AUTOSAR XML (schema 00046)
package /ComponentTypes
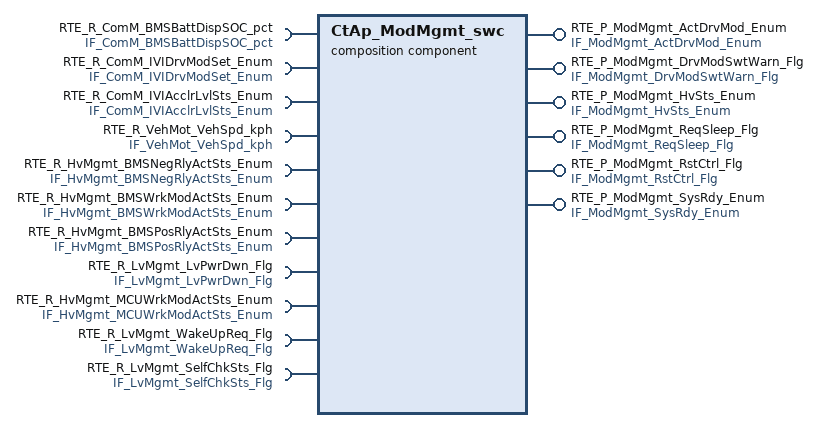
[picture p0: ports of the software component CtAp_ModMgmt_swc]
  composition sw component type CtAp_ModMgmt_swc
    5 x provide port:
      RTE_P_ModMgmt_ActDrvMod_Enum: nonqueued-sender-com-spec{data-element=tec_ModMgmt_ActDrvMod_Enum, init-value=0}, provided-interface=IF_ModMgmt_ActDrvMod_Enum
      RTE_P_ModMgmt_DrvModSwtWarn_Flg: nonqueued-sender-com-spec{data-element=tec_ModMgmt_DrvModSwtWarn_Flg, init-value=0}, provided-interface=IF_ModMgmt_DrvModSwtWarn_Flg
      RTE_P_ModMgmt_HvSts_Enum: nonqueued-sender-com-spec{data-element=tec_ModMgmt_HvSts_Enum, init-value=0}, provided-interface=IF_ModMgmt_HvSts_Enum
      RTE_P_ModMgmt_ReqSleep_Flg: nonqueued-sender-com-spec{data-element=tec_ModMgmt_ReqSleep_Flg, init-value=0}, provided-interface=IF_ModMgmt_ReqSleep_Flg
      RTE_P_ModMgmt_RstCtrl_Flg: nonqueued-sender-com-spec{data-element=tec_ModMgmt_RstCtrl_Flg, init-value=0}, provided-interface=IF_ModMgmt_RstCtrl_Flg
    4 x require port:
      RTE_R_ComM_BMSBattDispSOC_pct: nonqueued-receiver-com-spec{data-element=tec_ComM_BMSBattDispSOC_pct, filter=data-filter-type=ALWAYS, init-value=0}, required-interface=IF_ComM_BMSBattDispSOC_pct
      RTE_R_ComM_IVIDrvModSet_Enum: nonqueued-receiver-com-spec{data-element=tec_ComM_IVIDrvModSet_Enum, filter=data-filter-type=ALWAYS, init-value=0}, required-interface=IF_ComM_IVIDrvModSet_Enum
      RTE_R_ComM_IVIAcclrLvlSts_Enum: nonqueued-receiver-com-spec{data-element=tec_ComM_IVIAcclrLvlSts_Enum, filter=data-filter-type=ALWAYS, init-value=0}, required-interface=IF_ComM_IVIAcclrLvlSts_Enum
      RTE_R_VehMot_VehSpd_kph: nonqueued-receiver-com-spec{data-element=tec_VehMot_VehSpd_kph, filter=data-filter-type=ALWAYS, init-value=0}, required-interface=IF_VehMot_VehSpd_kph
    provide port RTE_P_ModMgmt_SysRdy_Enum: nonqueued-sender-com-spec{data-element=tec_ModMgmt_SysRdy_Enum, init-value=0}, provided-interface=IF_ModMgmt_SysRdy_Enum
    7 x require port:
      RTE_R_HvMgmt_BMSNegRlyActSts_Enum: nonqueued-receiver-com-spec{data-element=tec_HvMgmt_BMSNegRlyActSts_Enum, filter=data-filter-type=ALWAYS, init-value=0}, required-interface=IF_HvMgmt_BMSNegRlyActSts_Enum
      RTE_R_HvMgmt_BMSWrkModActSts_Enum: nonqueued-receiver-com-spec{data-element=tec_HvMgmt_BMSWrkModActSts_Enum, filter=data-filter-type=ALWAYS, init-value=0}, required-interface=IF_HvMgmt_BMSWrkModActSts_Enum
      RTE_R_HvMgmt_BMSPosRlyActSts_Enum: nonqueued-receiver-com-spec{data-element=tec_HvMgmt_BMSPosRlyActSts_Enum, filter=data-filter-type=ALWAYS, init-value=0}, required-interface=IF_HvMgmt_BMSPosRlyActSts_Enum
      RTE_R_LvMgmt_LvPwrDwn_Flg: nonqueued-receiver-com-spec{data-element=tec_LvMgmt_LvPwrDwn_Flg, filter=data-filter-type=ALWAYS, init-value=0}, required-interface=IF_LvMgmt_LvPwrDwn_Flg
      RTE_R_HvMgmt_MCUWrkModActSts_Enum: nonqueued-receiver-com-spec{data-element=tec_HvMgmt_MCUWrkModActSts_Enum, filter=data-filter-type=ALWAYS, init-value=0}, required-interface=IF_HvMgmt_MCUWrkModActSts_Enum
      RTE_R_LvMgmt_WakeUpReq_Flg: nonqueued-receiver-com-spec{data-element=tec_LvMgmt_WakeUpReq_Flg, filter=data-filter-type=ALWAYS, init-value=0}, required-interface=IF_LvMgmt_WakeUpReq_Flg
      RTE_R_LvMgmt_SelfChkSts_Flg: nonqueued-receiver-com-spec{data-element=tec_LvMgmt_SelfChkSts_Flg, filter=data-filter-type=ALWAYS, init-value=0}, required-interface=IF_LvMgmt_SelfChkSts_Flg
    component CtAp_DrvMod: type=CtAp_DrvMod
    component CtAp_VehStat: type=CtAp_VehStat
    delegate CtAp_DrvMod.RTE_P_ModMgmt_ActDrvMod_Enum <-> outer port RTE_P_ModMgmt_ActDrvMod_Enum
    delegate CtAp_DrvMod.RTE_P_ModMgmt_DrvModSwtWarn_Flg <-> outer port RTE_P_ModMgmt_DrvModSwtWarn_Flg
    delegate CtAp_VehStat.RTE_P_ModMgmt_HvSts_Enum <-> outer port RTE_P_ModMgmt_HvSts_Enum
    delegate CtAp_VehStat.RTE_P_ModMgmt_ReqSleep_Flg <-> outer port RTE_P_ModMgmt_ReqSleep_Flg
    delegate CtAp_VehStat.RTE_P_ModMgmt_RstCtrl_Flg <-> outer port RTE_P_ModMgmt_RstCtrl_Flg
    delegate CtAp_VehStat.RTE_P_ModMgmt_SysRdy_Enum <-> outer port RTE_P_ModMgmt_SysRdy_Enum
    delegate CtAp_DrvMod.RTE_R_ComM_BMSBattDispSOC_pct <-> outer port RTE_R_ComM_BMSBattDispSOC_pct
    delegate CtAp_DrvMod.RTE_R_ComM_IVIAcclrLvlSts_Enum <-> outer port RTE_R_ComM_IVIAcclrLvlSts_Enum
    delegate CtAp_DrvMod.RTE_R_ComM_IVIDrvModSet_Enum <-> outer port RTE_R_ComM_IVIDrvModSet_Enum
    delegate CtAp_VehStat.RTE_R_HvMgmt_BMSNegRlyActSts_Enum <-> outer port RTE_R_HvMgmt_BMSNegRlyActSts_Enum
    delegate CtAp_VehStat.RTE_R_HvMgmt_BMSPosRlyActSts_Enum <-> outer port RTE_R_HvMgmt_BMSPosRlyActSts_Enum
    delegate CtAp_VehStat.RTE_R_HvMgmt_BMSWrkModActSts_Enum <-> outer port RTE_R_HvMgmt_BMSWrkModActSts_Enum
    delegate CtAp_VehStat.RTE_R_HvMgmt_MCUWrkModActSts_Enum <-> outer port RTE_R_HvMgmt_MCUWrkModActSts_Enum
    delegate CtAp_VehStat.RTE_R_LvMgmt_LvPwrDwn_Flg <-> outer port RTE_R_LvMgmt_LvPwrDwn_Flg
    delegate CtAp_VehStat.RTE_R_LvMgmt_SelfChkSts_Flg <-> outer port RTE_R_LvMgmt_SelfChkSts_Flg
    delegate CtAp_VehStat.RTE_R_LvMgmt_WakeUpReq_Flg <-> outer port RTE_R_LvMgmt_WakeUpReq_Flg
    delegate CtAp_VehStat.RTE_R_VehMot_VehSpd_kph <-> outer port RTE_R_VehMot_VehSpd_kph
